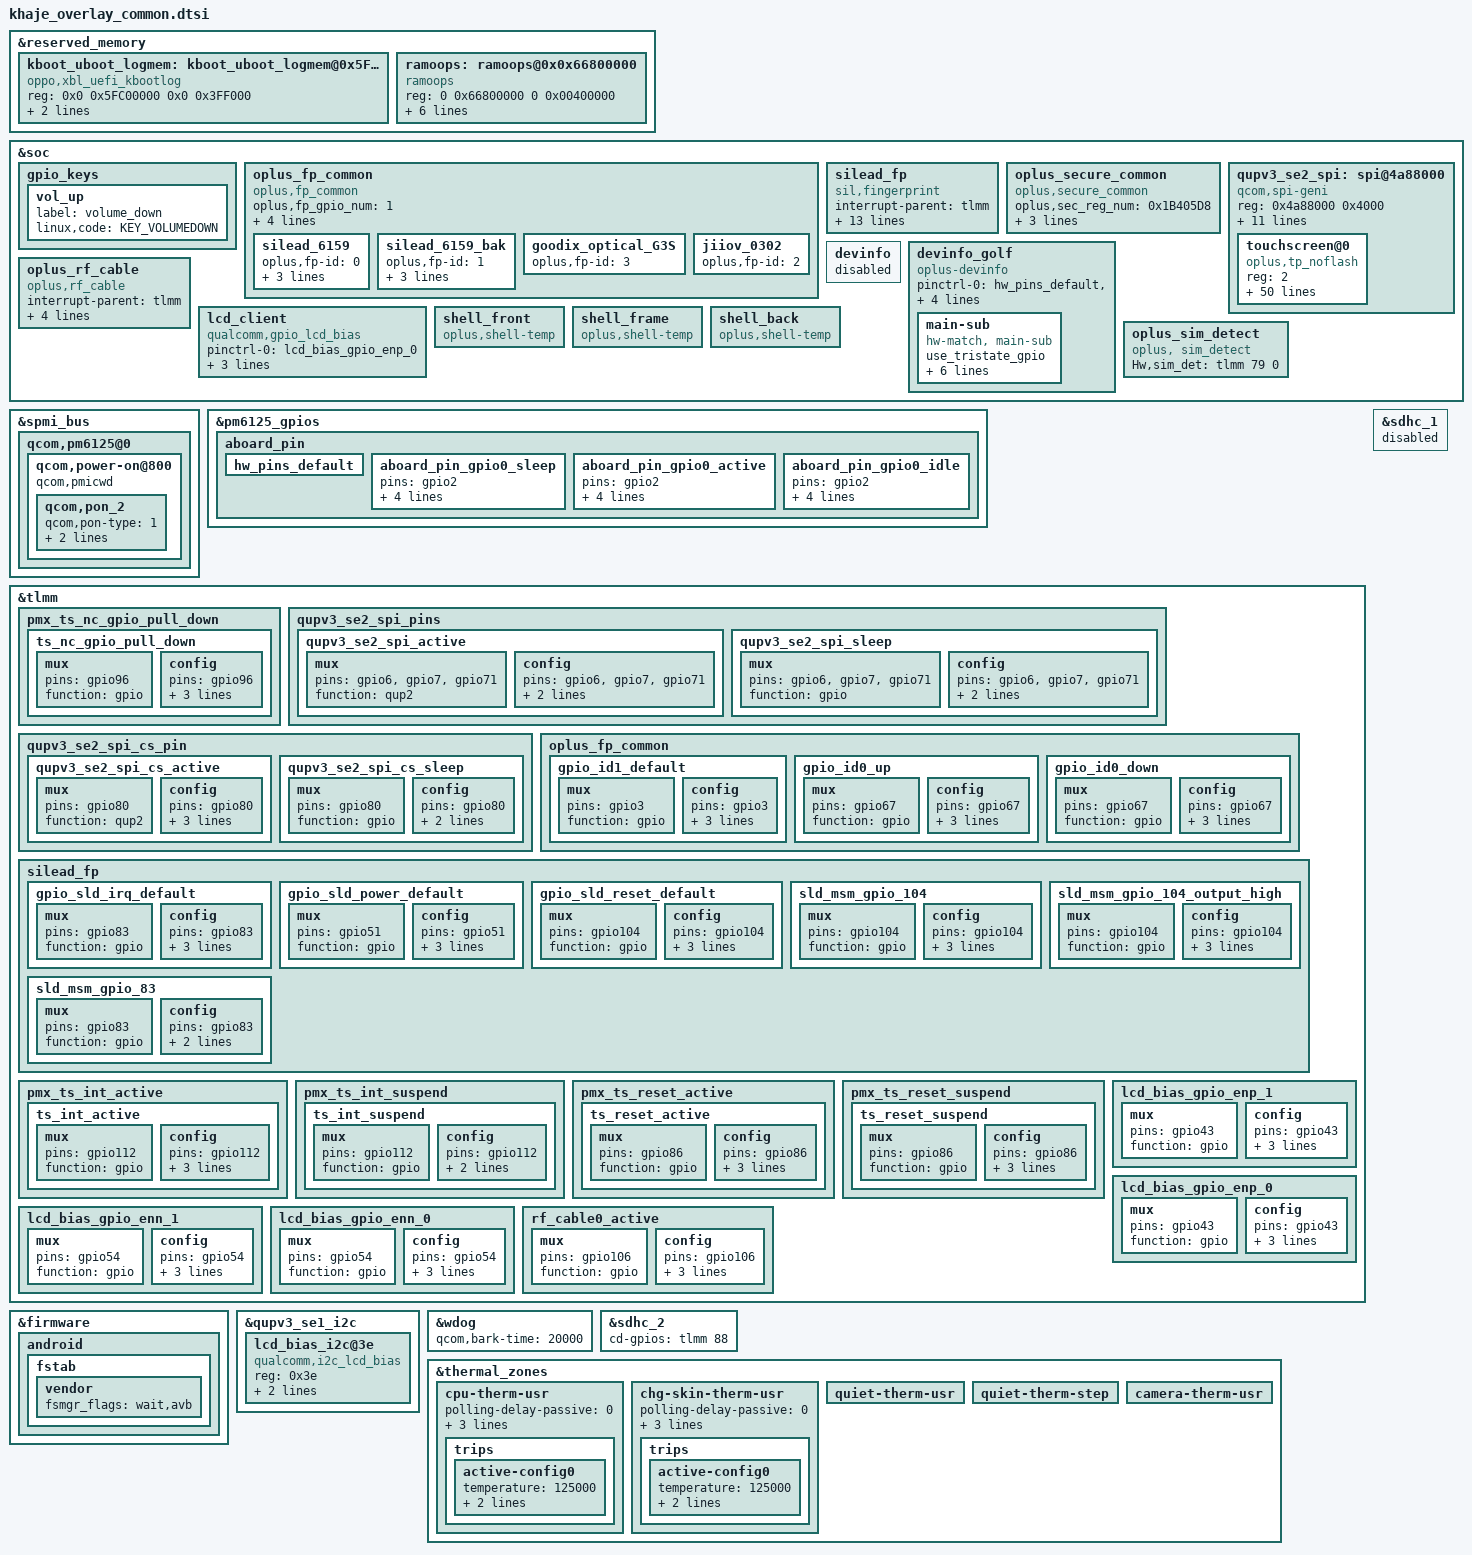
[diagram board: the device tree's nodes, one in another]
#include "camera/khaje-golf-camera-overlay.dtsi"
#include "sensor/golf-sensor-mtp.dtsi"


// xbl_uefi_mem address get from boot_images Core.dsc.inc file: PcdEmbeddedFdBaseAddress + SERIAL_BUFFER_OFFSET,0x5FC00000+0x3F7000
// kernel boot log: 0x5FC00000~ 0x5FFF7000
&reserved_memory {
	kboot_uboot_logmem: kboot_uboot_logmem@0x5FC00000 {
		reg = <0x0 0x5FC00000 0x0 0x3FF000>;
		compatible = "oppo,xbl_uefi_kbootlog";
		xbluefi-offset = <0x3F7000>;
		no-map;
	};

	ramoops: ramoops@0x0x66800000 {
		compatible = "ramoops";
		reg = <0 0x66800000 0 0x00400000>;
		record-size =  <0x40000>; //256x1024
		console-size = <0x40000>;
		ftrace-size =  <0x40000>;
		pmsg-size=         <0x200000>;
		devinfo-size=  <0x01000>;
		ecc-size=          <0x0>;
	};
};
//bengal-qrd.dtsi
&soc {
	gpio_keys {
		vol_up {
			/delete-property/ label;
			label = "volume_down";
			/delete-property/ linux,code;
			linux,code = <KEY_VOLUMEDOWN>;
		};
	};

	/delete-node/ oplus_fp_common;
	oplus_fp_common {
		compatible = "oplus,fp_common";
		oplus,fp_gpio_num = <1>;
		oplus,fp_gpio_0 = <&tlmm 67 0x0>;
		pinctrl-names = "gpio_id0_up", "gpio_id0_down";
		pinctrl-0 = <&gpio_id0_up>;
		pinctrl-1 = <&gpio_id0_down>;
		oplus,one_gpio_for_three_ic = <1>;
		/delete-node/ jiiov_0302;
		/delete-node/ goodix_optical_G3S;
        silead_6159 {
            oplus,fp-id = <0>; /* fp id mapping table */
            vendor-chip = <29>; /* please refer to the struct fp_vendor_t in oppo_fp_commmon.n */
            eng-menu = "-1, -1"; /* represents SNR, inclination test item in engineer menu, and 0/1 means off/on */
            chip-name = "S_gsl6159"; /* /proc/fp_id, will be displayed in engineer menu  */
        };
        silead_6159_bak {
            oplus,fp-id = <1>; /* fp id mapping table */
            vendor-chip = <29>; /* please refer to the struct fp_vendor_t in oppo_fp_commmon.n */
            eng-menu = "-1, -1"; /* represents SNR, inclination test item in engineer menu, and 0/1 means off/on */
            chip-name = "S_gsl6159"; /* /proc/fp_id, will be displayed in engineer menu  */
        };
	goodix_optical_G3S {
	    /delete-property/ oplus,fp-id;
	    oplus,fp-id = <3>; /* fp id mapping table */
	};
	jiiov_0302 {
	    /delete-property/ oplus,fp-id;
            oplus,fp-id = <2>; /* fp id mapping table */
        };
	};
    silead_fp {
        status = "ok";
        compatible = "sil,fingerprint";
        interrupt-parent = <&tlmm>;
        interrupts = <83 0x0>;
        irq-gpios = <&tlmm 83 0x1>;
        rst-gpios = <&tlmm 104 0x0>;
        avdd-gpios = <&tlmm 51 0x0>;
        spi-max-frequency = <4800000>;
        qcom,qup-id = <6>;
        sld,enable-via-gpio;
        pinctrl-names = "default", "sld_reset_reset", "sld_reset_active", "sld_irq_active";
        pinctrl-0 = <&gpio_sld_irq_default>, <&gpio_sld_power_default>, <&gpio_sld_reset_default>;
        pinctrl-1 = <&sld_msm_gpio_104>;
        pinctrl-2 = <&sld_msm_gpio_104_output_high>;
        pinctrl-3 = <&sld_msm_gpio_83>;
    };

    // #ifdef OPLUS_FEATURE_SECURITY_COMMON
    oplus_secure_common {
        compatible = "oplus,secure_common";
		oplus,sec_reg_num = <0x1B405D8>;
		oplus,sec_en_anti_reg = <0x1B401CC>;
		oplus,sec_override1_reg = <0x7860C0>;
		oplus,override1_en_value = <0x1>;
    };
    //#endif /* OPLUS_FEATURE_SECURITY_COMMON */

	qupv3_se2_spi: spi@4a88000 {
		compatible = "qcom,spi-geni";
		#address-cells = <1>;
		#size-cells = <0>;
		reg = <0x4a88000 0x4000>;
		reg-names = "se_phys";
		clock-names = "se-clk", "m-ahb", "s-ahb";
		clocks = <&gcc GCC_QUPV3_WRAP0_S2_CLK>,
		<&gcc GCC_QUPV3_WRAP_0_M_AHB_CLK>,
		<&gcc GCC_QUPV3_WRAP_0_S_AHB_CLK>;
		pinctrl-names = "default", "sleep";
		pinctrl-0 = <&qupv3_se2_spi_active &qupv3_se2_spi_cs_active>;
		pinctrl-1 = <&qupv3_se2_spi_sleep &qupv3_se2_spi_cs_sleep>;

		interrupts = <GIC_SPI 329 IRQ_TYPE_LEVEL_HIGH>;
		spi-max-frequency = <50000000>;
		qcom,wrapper-core = <&qupv3_0>;
		dmas = <&gpi_dma0 0 2 1 64 0>,
		<&gpi_dma0 1 2 1 64 0>;
		dma-names = "tx", "rx";
		status = "disabled";
	};
        devinfo {
                status = "disabled";
        };
        devinfo_golf {
                compatible = "oplus-devinfo";

                pinctrl-names = "default", "sleep", "active", "idle";
                pinctrl-0 = <&hw_pins_default &ts_nc_gpio_pull_down>;
                pinctrl-1 = <&aboard_pin_gpio0_sleep>;
                pinctrl-2 = <&aboard_pin_gpio0_active>;
                pinctrl-3 = <&aboard_pin_gpio0_idle>;
                main-sub {
                        use_tristate_gpio;
			devinfo-match-ignore-list = <21091 21261 21262 21265 21266 21267 21268>;
                        compatible = "hw-match, main-sub";
                        aboard-gpio0 = <&pm6125_gpios 2 0>;
                        aboard-patterns = <0 1 1 1 1 2 2 2>;    /*0[high-resistance] 1[pull-down] 2[pull-up]*/
                        /*main board*/
                        match-projects = <21091 21261 21262 21266 21268 21263 21265 21267>;
                };
        };

	//#ifdef VENDOR_EDIT
	oplus_rf_cable {
		compatible = "oplus,rf_cable";
		interrupt-parent = <&tlmm>;
		rf_cable_support_num = <1>;
		rf,cable0-gpio = <&tlmm 106 0>;
		rf,cable-support-timer = <0>;
		pinctrl-names = "rf_cable_active";
		pinctrl-0 = <&rf_cable0_active>;
	};
	//#endif /* VENDOR_EDIT */

	lcd_client {
		compatible = "qualcomm,gpio_lcd_bias";
		pinctrl-names = "lcd_bias_gpio_enp0","lcd_bias_gpio_enp1","lcd_bias_gpio_enn0","lcd_bias_gpio_enn1";
		pinctrl-0 = <&lcd_bias_gpio_enp_0>;
		pinctrl-1 = <&lcd_bias_gpio_enp_1>;
		pinctrl-2 = <&lcd_bias_gpio_enn_0>;
		pinctrl-3 = <&lcd_bias_gpio_enn_1>;
		status = "okay";
	};
	//#ifdef OPLUS_FEATURE_THERMAL_HORAE
    shell_front {
        compatible = "oplus,shell-temp";
    };

    shell_frame {
        compatible = "oplus,shell-temp";
    };

    shell_back {
        compatible = "oplus,shell-temp";
    };
    //#endif /* OPLUS_FEATURE_THERMAL_HORAE */

	//#ifdef OPLUS_FEATURE_TP_BASIC
		oplus_sim_detect {
			compatible = "oplus, sim_detect";
			Hw,sim_det = <&tlmm 79 0>;
		};
	//#endif /* OPLUS_FEATURE_TP_BASIC */
};

&spmi_bus {
	qcom,pm6125@0 {
		qcom,power-on@800 {
			qcom,pmicwd;
			qcom,pon_2 {
				qcom,pon-type = <1>;
				qcom,pull-up = <1>;
				linux,code = <KEY_VOLUMEUP>;
			};
		};
    };
};
&pm6125_gpios {
        aboard_pin {
                hw_pins_default:hw_pins_default {
                };

                aboard_pin_gpio0_sleep:aboard_pin_gpio0_sleep {
                pins = "gpio2";
                        function = "normal";
                        bias-pull-down;
                        input-enable;
                        power-source = <0>;
                };

                aboard_pin_gpio0_active:aboard_pin_gpio0_active {
                pins = "gpio2";
                        function = "normal";
                        bias-pull-up;
                        input-enable;
                        power-source = <0>;
                };

                aboard_pin_gpio0_idle:aboard_pin_gpio0_idle {
                pins = "gpio2";
                        function = "normal";
                        bias-disable;
                        input-enable;
                        power-source = <0>;
                };
        };
};

&tlmm {
	pmx_ts_nc_gpio_pull_down {
		ts_nc_gpio_pull_down: ts_nc_gpio_pull_down {
			mux {
				pins = "gpio96";
				function = "gpio";
			};
				config {
				pins = "gpio96";
				drive-strength = <2>;
				input-enable;
				bias-pull-down;
			};
		};
	};

	/delete-node/ qupv3_se2_i2c_pins;
	qupv3_se2_spi_pins: qupv3_se2_spi_pins {
		qupv3_se2_spi_active: qupv3_se2_spi_active {
			mux {
				pins = "gpio6", "gpio7", "gpio71";
				function = "qup2";
			};

			config {
				pins = "gpio6", "gpio7", "gpio71";
				drive-strength = <8>;
				bias-pull-down;
			};
		};

		qupv3_se2_spi_sleep: qupv3_se2_spi_sleep {
			mux {
				pins = "gpio6", "gpio7", "gpio71";
				function = "gpio";
			};

			config {
				pins = "gpio6", "gpio7", "gpio71";
				drive-strength = <2>;
				bias-pull-down;
			};
		};
	};

	qupv3_se2_spi_cs_pin: qupv3_se2_spi_cs_pin {
		qupv3_se2_spi_cs_active: qupv3_se2_spi_cs_active {
			mux {
				pins = "gpio80";
				function = "qup2";
			};

			config {
				pins = "gpio80";
				drive-strength = <8>;
				output-high;
				bias-pull-up;
			};
		};

		qupv3_se2_spi_cs_sleep: qupv3_se2_spi_cs_sleep {
			mux {
				pins = "gpio80";
				function = "gpio";
			};

			config {
				pins = "gpio80";
				drive-strength = <2>;
				bias-pull-down;
			};
		};
	};

	oplus_fp_common{
		gpio_id1_default: gpio_id1_default {
			mux {
				pins = "gpio3";
				function = "gpio";
			};
			config {
				pins = "gpio3";
				drive-strength = <2>;
				bias-pull-up;
				input-enable;
			};
		};
		gpio_id0_up: gpio_id0_up {
			mux {
				pins = "gpio67";
				function = "gpio";
			};
			config {
				pins = "gpio67";
				drive-strength = <2>;
				bias-pull-up;
				input-enable;
			};
		};
		gpio_id0_down: gpio_id0_down {
			mux {
				pins = "gpio67";
				function = "gpio";
			};
			config {
				pins = "gpio67";
				drive-strength = <2>;
				bias-pull-down;
				input-enable;
			};
		};
	};

    silead_fp{
	    gpio_sld_irq_default: gpio_sld_irq_default {
	        mux {
	            pins = "gpio83";
	            function = "gpio";
	        };
	        config {
	            pins = "gpio83";
	            drive-strength = <2>;
	            bias-pull-down;
	            input-enable;
	        };
	    };
	    gpio_sld_power_default: gpio_sld_power_default {
	        mux {
	            pins = "gpio51";
	            function = "gpio";
	        };
	        config {
	            pins = "gpio51";
	            drive-strength = <2>;
	            bias-disable;
	            output-low;
	        };
	    };
	    gpio_sld_reset_default: gpio_sld_reset_default {
	        mux {
	            pins = "gpio104";
	            function = "gpio";
	        };
	        config {
	            pins = "gpio104";
	            drive-strength = <2>;
	            bias-disable;
	            output-low;
	        };
	    };
        sld_msm_gpio_104: sld_msm_gpio_104 {
            mux {
                pins = "gpio104";
                function = "gpio";
            };

            config {
                pins = "gpio104";
                drive-strength = <2>;
                bias-disable;
                output-low;
            };
        };

        // GPIO_104 : FP_RESET_N, state device active
        sld_msm_gpio_104_output_high: sld_msm_gpio_104_output_high {
            mux {
                pins = "gpio104";
                function = "gpio";
            };

            config {
                pins = "gpio104";
                drive-strength = <2>;
                bias-disable;
                output-high;
            };
        };

        // GPIO_83 : FP_INT_N
        sld_msm_gpio_83: sld_msm_gpio_83 {
            mux {
                pins = "gpio83";
                function = "gpio";
            };

            config {
                pins = "gpio83";
                drive-strength = <2>;
                bias-pull-down;
            };
        };
	};

	pmx_ts_int_active {
		ts_int_active: ts_int_active {
			mux {
				pins = "gpio112";
				function = "gpio";
			};

			config {
				pins = "gpio112";
				drive-strength = <8>;
				bias-pull-up;
				input-enable;
			};
		};
	};

	pmx_ts_int_suspend {
		ts_int_suspend: ts_int_suspend {
			mux {
				pins = "gpio112";
				function = "gpio";
			};

			config {
				pins = "gpio112";
				drive-strength = <2>;
				bias-pull-down;
			};
		};
	};

	pmx_ts_reset_active {
		ts_reset_active: ts_reset_active {
			mux {
				pins = "gpio86";
				function = "gpio";
			};

			config {
				pins = "gpio86";
				drive-strength = <8>;
				output-high;
				bias-pull-up;
			};
		};
	};

	pmx_ts_reset_suspend {
		ts_reset_suspend: ts_reset_suspend {
			mux {
				pins = "gpio86";
				function = "gpio";
			};

			config {
				pins = "gpio86";
				drive-strength = <2>;
				output-low;
				bias-pull-down;
			};
		};
	};

	lcd_bias_gpio_enp_1: lcd_bias_gpio_enp_1 {
		mux {
			pins = "gpio43";
			function = "gpio";
		};

		config {
			pins = "gpio43";
			drive-strength = <8>;
			output-high;
			bias-pull-up;
		};
	};

	lcd_bias_gpio_enp_0: lcd_bias_gpio_enp_0 {
		mux {
			pins = "gpio43";
			function = "gpio";
		};

		config {
			pins = "gpio43";
			drive-strength = <2>;
			output-low;
			bias-pull-down;
		};
	};

	lcd_bias_gpio_enn_1: lcd_bias_gpio_enn_1 {
		mux {
			pins = "gpio54";
			function = "gpio";
		};

		config {
			pins = "gpio54";
			drive-strength = <8>;
			output-high;
			bias-pull-up;
		};
	};

	lcd_bias_gpio_enn_0: lcd_bias_gpio_enn_0 {
		mux {
			pins = "gpio54";
			function = "gpio";
		};

		config {
			pins = "gpio54";
			drive-strength = <2>;
			output-low;
			bias-pull-down;
		};
	};

	//#ifdef VENDOR_EDIT
	rf_cable0_active: rf_cable0_active {
		mux {
			pins = "gpio106";
			function = "gpio";
		};
		config {
			pins = "gpio106";
			drive-strength = <2>;
			input-enable;
			bias-pull-up;
		};
	};
	//#endif /* VENDOR_EDIT */

};

&firmware {
	android {
		fstab {
			vendor {
				/delete-property/ fsmgr_flags;
				fsmgr_flags = "wait,avb";
			};
		};
	};
};
&qupv3_se1_i2c {
	lcd_bias_i2c@3e {
		compatible = "qualcomm,i2c_lcd_bias";
		reg = <0x3e>;
		qualcomm,enp = <&tlmm 52 0x0>;
		qualcomm,enn = <&tlmm 54 0x0>;
		status = "okay";
	};
};
//bengal-audio-overlay.dtsi

&qupv3_se2_spi {
	status = "ok";
	touchscreen@0 {
		compatible = "oplus,tp_noflash";
		reg = <2>;
		chip-name = "NF_NT36672C";
		status = "ok";
		tcsh_flag;

		spi-max-frequency = <12000000>;    /*4800000,9600000,15000000,19200000*/
		reset-gpio = <&tlmm 86 0x00>;
		interrupt-parent = <&tlmm>;
		interrupts = <112  0x0>;
		irq-gpio = <&tlmm 112 0x2002>;
		cs-gpio = <&tlmm 80 0x2002>;

		touchpanel,irq_need_dev_resume_time = <500>;
		touchpanel,max-num-support = <10>;
		touchpanel,tx-rx-num = <18 36>;			/*hd:18  32*/
		touchpanel,panel-coords = <1080 2412>;
		touchpanel,display-coords = <1080 2412>;	/*hd:720 1612*/
		touchpanel,touchmajor-limit = <0 54>;

		platform_support_project = <21261 21262 21263 21265 21266 21267 21268 21091>;	/*261-263: fhd; 264-266, 21091: hd*/
		platform_support_project_dir = <21261 21261 21261 21261 21261 21261 21261 21261>;
		platform_support_project_commandline = "default_commandline", "default_commandline", "default_commandline",	/*fhd*/
			"default_commandline", "default_commandline", "default_commandline", "default_commandline", "default_commandline";	/* hd*/
		platform_support_project_external_name = "AA256", "AA256", "AA256", "AA256", "AA256", "AA256", "AA256", "AA256";
		pinctrl-names = "default", "pin_set_low", "pin_set_high";
		pinctrl-0 = <&ts_int_active &ts_reset_active>;
		pinctrl-1 = <&ts_int_suspend &ts_reset_suspend>;
		pinctrl-2 = <&ts_int_active &ts_reset_active>;

		tp_type = <7>;	/*TM*/

		incell_screen;
		irq_need_dev_resume_ok;
		fw_edge_limit_support;
		black_gesture_support;
		charger_pump_support;
		headset_pump_support;
		esd_handle_support;
		//spurious_fingerprint_support;
		//lcd_trigger_fp_check;
		black_gesture_test_support;
		noflash_support;
		smart_gesture_support;
		pressure_report_support;
		fw_update_app_support;
		game_switch_support;
		drlimit_remove_support;
		lcd_trigger_load_tp_fw_support;
		suspend_gesture_cfg;
		fw_update_in_probe_with_headfile;
		health_monitor_v2_support;

		touchpanel,button-type = <4>;
		exception_upload_support;
	};
};

//modify bark time to 20s
&wdog {
	/delete-property/ qcom,bark-time;
	qcom,bark-time = <20000>;
};

/* #ifdef OPLUS_FEATURE_EMMC_DRIVER */
&sdhc_1 {
       status = "disabled";
};

&sdhc_2 {
       cd-gpios = <&tlmm 88 GPIO_ACTIVE_HIGH>;
       status = "ok";
};
/* #endif */
//#ifdef OPLUS_TEMP_NTC
&thermal_zones {
        cpu-therm-usr {
                polling-delay-passive = <0>;
                polling-delay = <0>;
                thermal-governor = "user_space";
                wake-capable-sensor;
                trips {
                        active-config0 {
                                temperature = <125000>;
                                hysteresis = <1000>;
                                type = "passive";
                        };
                };
        };

        chg-skin-therm-usr {
                polling-delay-passive = <0>;
                polling-delay = <0>;
                thermal-governor = "user_space";
                wake-capable-sensor;
                trips {
                        active-config0 {
                                temperature = <125000>;
                                hysteresis = <1000>;
                                type = "passive";
                        };
                };
        };

        quiet-therm-usr {
                /delete-property/ thermal-sensors;
        };

        quiet-therm-step {
                /delete-property/ thermal-sensors;
        };

        camera-therm-usr {
                /delete-property/ thermal-sensors;
        };
};
//#endif
